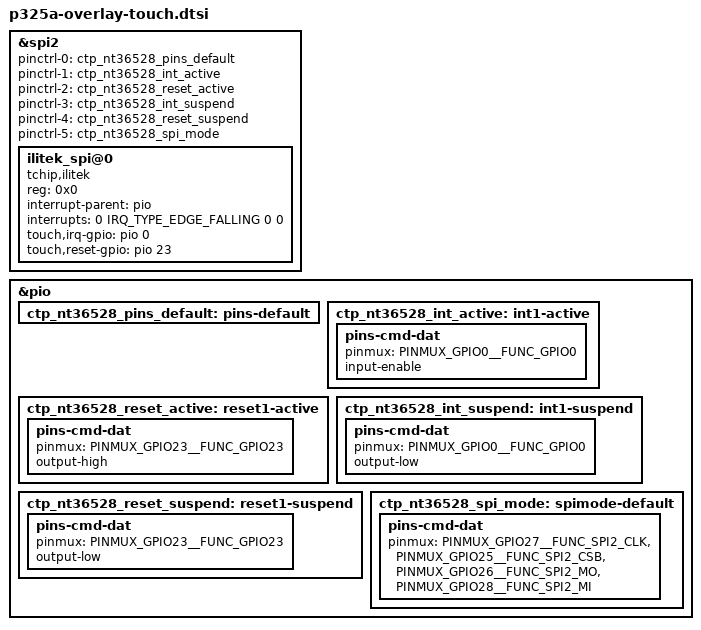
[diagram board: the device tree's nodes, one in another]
/*[TN.NJDC] touch overlay file.start*/
&spi2 {
		status = "ok";
		#address-cells = <1>;
		#size-cells = <0>;
		pinctrl-names = "default", "nt36528_int_active",
		"nt36528_reset_active", "nt36528_int_suspend",
		"nt36528_reset_suspend", "nt36528_spi_mode";

		pinctrl-0 = <&ctp_nt36528_pins_default>;
		pinctrl-1 = <&ctp_nt36528_int_active>;
		pinctrl-2 = <&ctp_nt36528_reset_active>;
		pinctrl-3 = <&ctp_nt36528_int_suspend>;
		pinctrl-4 = <&ctp_nt36528_reset_suspend>;
		pinctrl-5 = <&ctp_nt36528_spi_mode>;

       ilitek_spi@0 {
              compatible = "tchip,ilitek";
              reg = <0x0>;
              interrupt-parent = <&pio>;
              interrupts = <0 IRQ_TYPE_EDGE_FALLING 0 0>;

              touch,irq-gpio = <&pio 0 0x2>;
              touch,reset-gpio = <&pio 23 0x0>;
       };
};

&pio {
	ctp_nt36528_pins_default: pins-default {
	};
	ctp_nt36528_int_active: int1-active {
		pins-cmd-dat {
			pinmux = <PINMUX_GPIO0__FUNC_GPIO0>;
			input-enable;
		};
	};
	ctp_nt36528_reset_active: reset1-active {
		pins-cmd-dat {
			pinmux = <PINMUX_GPIO23__FUNC_GPIO23>;
			output-high;
		};
	};
	ctp_nt36528_int_suspend: int1-suspend {
		pins-cmd-dat {
			pinmux = <PINMUX_GPIO0__FUNC_GPIO0>;
			output-low;
		};
	};
	ctp_nt36528_reset_suspend: reset1-suspend {
		pins-cmd-dat {
			pinmux = <PINMUX_GPIO23__FUNC_GPIO23>;
			output-low;
		};
	};
	ctp_nt36528_spi_mode: spimode-default {
		pins-cmd-dat {
			pinmux = <PINMUX_GPIO27__FUNC_SPI2_CLK>,
				<PINMUX_GPIO25__FUNC_SPI2_CSB>,
				<PINMUX_GPIO26__FUNC_SPI2_MO>,
				<PINMUX_GPIO28__FUNC_SPI2_MI>;
		};
	};
};
/*[TN.NJDC] touch overlay file.end*/
